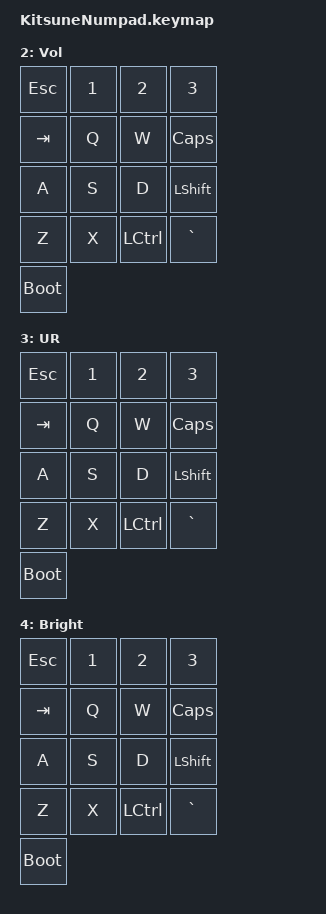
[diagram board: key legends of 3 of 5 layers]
#include <behaviors.dtsi>
#include <dt-bindings/zmk/keys.h>

/ {
    keymap {
        compatible = "zmk,keymap";
        display-name = "BASE";

        JassonLayout {
            bindings = <
                &kp ESC      &kp N1  &kp N2            &kp N3
                &kp TAB      &kp Q   &kp W             &kp CAPSLOCK
                &kp A        &kp S   &kp D             &kp LEFT_SHIFT
                &kp Z        &kp X   &kp LEFT_CONTROL  &kp GRAVE
                &bootloader
                &kp K_MUTE   
            >;
            sensor-bindings = <&inc_dec_kp C_VOL_UP C_VOL_DN>;
        };

        Numpad {
            display-name = "Num";
            bindings = <
                &kp ESC      &kp N1  &kp N2     &kp N3
                &kp N1      &kp N2   &kp N3     &kp CAPSLOCK
                &kp N4      &kp N5   &kp N6     &kp LEFT_SHIFT
                &kp N7      &kp N8   &kp N9     &kp GRAVE
                &bootloader
                &kp K_MUTE   
            >;
            sensor-bindings = <&inc_dec_kp C_VOL_UP C_VOL_DN>;
        };

        Volume {
            display-name = "Vol";
            bindings = <
                &kp ESC      &kp N1  &kp N2            &kp N3
                &kp TAB      &kp Q   &kp W             &kp CAPSLOCK
                &kp A        &kp S   &kp D             &kp LEFT_SHIFT
                &kp Z        &kp X   &kp LEFT_CONTROL  &kp GRAVE
                &bootloader
            >;
            sensor-bindings = <&inc_dec_kp C_VOL_UP C_VOL_DN>;
        };

        UndoRedo {
            display-name = "UR";
            bindings = <
                &kp ESC      &kp N1  &kp N2            &kp N3
                &kp TAB      &kp Q   &kp W             &kp CAPSLOCK
                &kp A        &kp S   &kp D             &kp LEFT_SHIFT
                &kp Z        &kp X   &kp LEFT_CONTROL  &kp GRAVE
                &bootloader
            >;
            sensor-bindings = <&inc_dec_kp K_REDO K_UNDO>;
        };

        Brightness {
            display-name = "Bright";
            bindings = <
                &kp ESC      &kp N1  &kp N2            &kp N3
                &kp TAB      &kp Q   &kp W             &kp CAPSLOCK
                &kp A        &kp S   &kp D             &kp LEFT_SHIFT
                &kp Z        &kp X   &kp LEFT_CONTROL  &kp GRAVE
                &bootloader
            >;
            sensor-bindings = <&inc_dec_kp C_BRIGHTNESS_INC C_BRIGHTNESS_DEC>;
        };

                extra_1 {
            status = "reserved";
        };

        extra_2 {
            status = "reserved";
        };

        extra_3 {
            status = "reserved";
        };

         extra_4 {
            status = "reserved";
        };

    };
};
